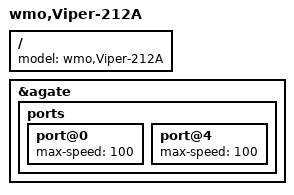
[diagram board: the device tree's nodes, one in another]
#include <coronet/a12-cpu.dtsi>

/ {
	model = "wmo,Viper-212A";
};

&agate {
	ports {
		/* ethX2/3 use two-pair M12 connector */
		port@0 { max-speed = <100>; };
		port@4 { max-speed = <100>; };
	};
};
